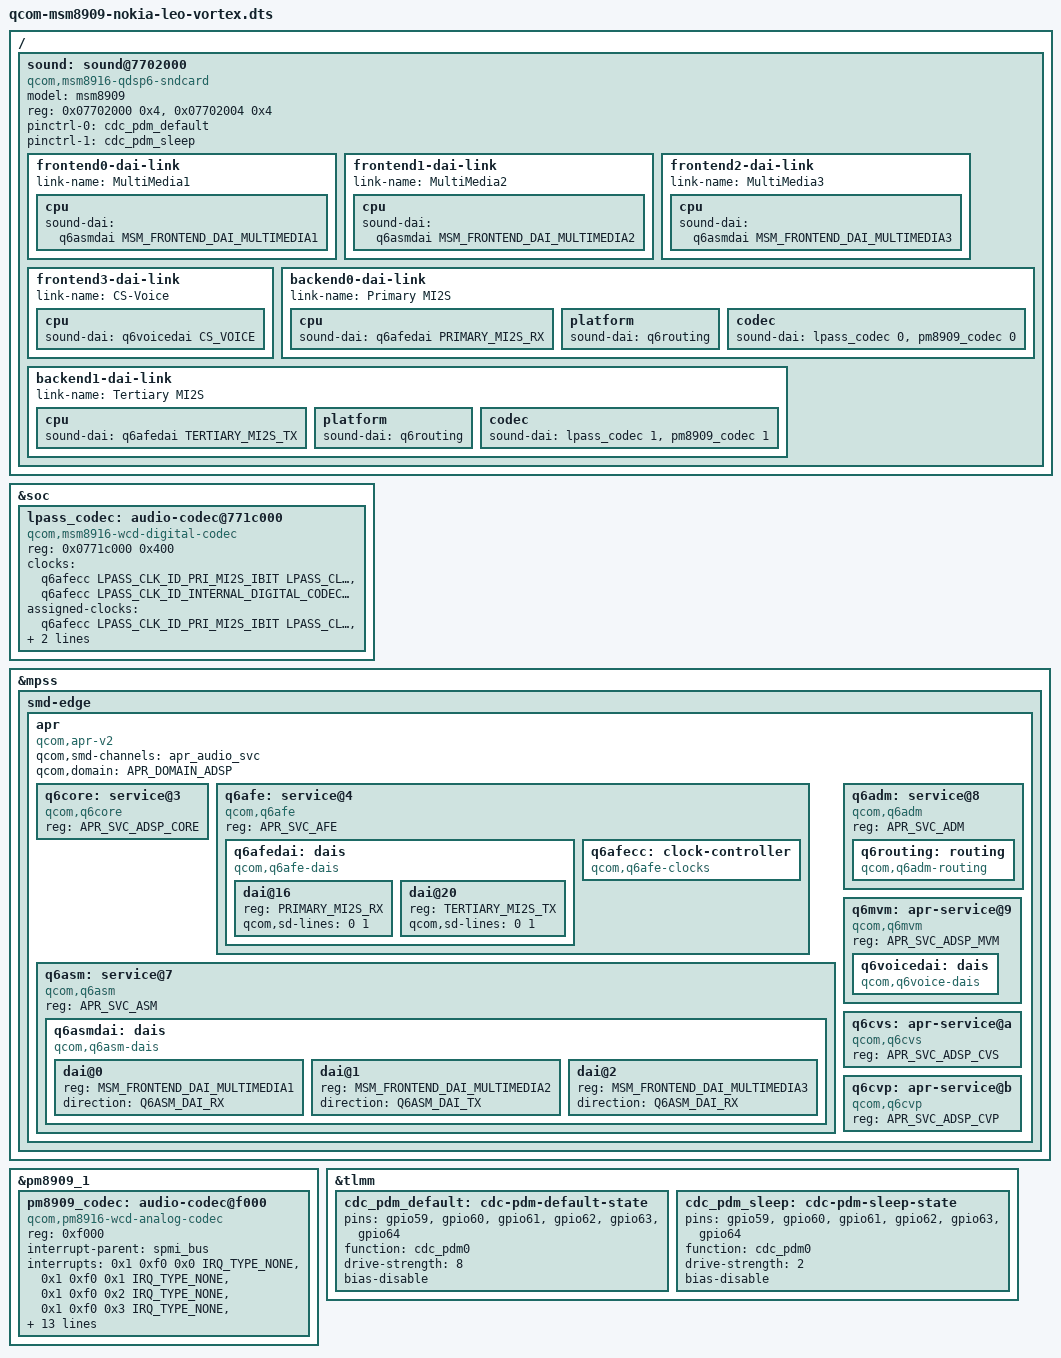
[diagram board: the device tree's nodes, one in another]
// SPDX-License-Identifier: GPL-2.0-only
/*
 * Nokia 6300 4G (nokia-leo) for Vortex: the postmarketOS / msm8916-mainline
 * device tree (tag v6.6-msm8916) plus audio, which that tree does not
 * describe for any MSM8909 device.
 *
 * Audio on MSM8909 goes through the QDSP6 services in the modem firmware,
 * like msm8916-modem-qdsp6.dtsi does for MSM8916 phones: the DSP owns the
 * audio interface (LPASS), the apps CPU drives the digital codec in the SoC
 * (0x771c000) and the analog codec in PM8909 (0xf000), linked by PDM.
 *
 * Differences from MSM8916, taken from Qualcomm's msm-3.18 MSM8909 sources:
 *  - GCC has no ULTAUDIO/CODEC_DIGCODEC clocks; the digital codec core
 *    clock is set through the DSP (AFE_PARAM_ID_CLOCK_SET with
 *    INTERNAL_DIGITAL_CODEC_CORE, as msm8952.c does by default), at the
 *    9.6 MHz of qcom,msm-mclk-freq.
 *  - The primary MI2S bit clock must be set the same way (CLOCK_SET,
 *    PRI_MI2S_IBIT, 1.536 MHz: msm8952.c mi2s_rx_clk).  The msm8916-qdsp6
 *    sound card sends the older LPAIF_CLK_CONFIG, which this firmware
 *    accepts but ignores: the stream then runs without the DSP taking any
 *    data.  The digital codec's "ahbix-clk" (the AHB interface clock, which
 *    the DSP handles on MSM8909) carries it instead, so it is on whenever
 *    the codec is.
 *  - PDM lines: gpio59-64, function cdc_pdm0 (msm8909-pinctrl.dtsi).
 *  - Codec supplies: L5 (1.8 V) for I/O and RX/TX, L13 (3.075 V) for the
 *    mic bias (msm-pm8909.dtsi).
 */

#include "qcom-msm8909-nokia-leo.dts"
#include <dt-bindings/soc/qcom,apr.h>
#include <dt-bindings/sound/qcom,q6afe.h>
#include <dt-bindings/sound/qcom,q6asm.h>
#include <dt-bindings/sound/qcom,q6voice.h>

/ {
	sound: sound@7702000 {
		compatible = "qcom,msm8916-qdsp6-sndcard";
		model = "msm8909";
		/* LPASS CSR I/O mux registers, the same on MSM8909 (msm8909-mtp.dtsi:
		 * csr_gp_io_mux_mic_ctl, csr_gp_io_mux_spkr_ctl); the driver
		 * refuses to probe without them */
		reg = <0x07702000 0x4>, <0x07702004 0x4>;
		reg-names = "mic-iomux", "spkr-iomux";

		pinctrl-0 = <&cdc_pdm_default>;
		pinctrl-1 = <&cdc_pdm_sleep>;
		pinctrl-names = "default", "sleep";

		frontend0-dai-link {
			link-name = "MultiMedia1";

			cpu {
				sound-dai = <&q6asmdai MSM_FRONTEND_DAI_MULTIMEDIA1>;
			};
		};

		frontend1-dai-link {
			link-name = "MultiMedia2";

			cpu {
				sound-dai = <&q6asmdai MSM_FRONTEND_DAI_MULTIMEDIA2>;
			};
		};

		frontend2-dai-link {
			link-name = "MultiMedia3";

			cpu {
				sound-dai = <&q6asmdai MSM_FRONTEND_DAI_MULTIMEDIA3>;
			};
		};

		frontend3-dai-link {
			link-name = "CS-Voice";

			cpu {
				sound-dai = <&q6voicedai CS_VOICE>;
			};
		};

		backend0-dai-link {
			link-name = "Primary MI2S";

			cpu {
				sound-dai = <&q6afedai PRIMARY_MI2S_RX>;
			};
			platform {
				sound-dai = <&q6routing>;
			};
			codec {
				sound-dai = <&lpass_codec 0>, <&pm8909_codec 0>;
			};
		};

		backend1-dai-link {
			link-name = "Tertiary MI2S";

			cpu {
				sound-dai = <&q6afedai TERTIARY_MI2S_TX>;
			};
			platform {
				sound-dai = <&q6routing>;
			};
			codec {
				sound-dai = <&lpass_codec 1>, <&pm8909_codec 1>;
			};
		};
	};
};

&soc {
	lpass_codec: audio-codec@771c000 {
		compatible = "qcom,msm8916-wcd-digital-codec";
		reg = <0x0771c000 0x400>;
		clocks = <&q6afecc LPASS_CLK_ID_PRI_MI2S_IBIT
				   LPASS_CLK_ATTRIBUTE_COUPLE_NO>,
			 <&q6afecc LPASS_CLK_ID_INTERNAL_DIGITAL_CODEC_CORE
				   LPASS_CLK_ATTRIBUTE_COUPLE_NO>;
		clock-names = "ahbix-clk", "mclk";
		/* DSP clocks only take their rate when they are switched on */
		assigned-clocks = <&q6afecc LPASS_CLK_ID_PRI_MI2S_IBIT
					    LPASS_CLK_ATTRIBUTE_COUPLE_NO>,
				  <&q6afecc LPASS_CLK_ID_INTERNAL_DIGITAL_CODEC_CORE
					    LPASS_CLK_ATTRIBUTE_COUPLE_NO>;
		assigned-clock-rates = <1536000>, <9600000>;
		#sound-dai-cells = <1>;
	};
};

&mpss {
	smd-edge {
		apr {
			compatible = "qcom,apr-v2";
			qcom,smd-channels = "apr_audio_svc";
			qcom,domain = <APR_DOMAIN_ADSP>;
			#address-cells = <1>;
			#size-cells = <0>;

			q6core: service@3 {
				compatible = "qcom,q6core";
				reg = <APR_SVC_ADSP_CORE>;
			};

			q6afe: service@4 {
				compatible = "qcom,q6afe";
				reg = <APR_SVC_AFE>;

				q6afedai: dais {
					compatible = "qcom,q6afe-dais";
					#address-cells = <1>;
					#size-cells = <0>;
					#sound-dai-cells = <1>;

					dai@16 {
						reg = <PRIMARY_MI2S_RX>;
						qcom,sd-lines = <0 1>;
					};

					dai@20 {
						reg = <TERTIARY_MI2S_TX>;
						qcom,sd-lines = <0 1>;
					};
				};

				q6afecc: clock-controller {
					compatible = "qcom,q6afe-clocks";
					#clock-cells = <2>;
				};
			};

			q6asm: service@7 {
				compatible = "qcom,q6asm";
				reg = <APR_SVC_ASM>;

				q6asmdai: dais {
					compatible = "qcom,q6asm-dais";
					#address-cells = <1>;
					#size-cells = <0>;
					#sound-dai-cells = <1>;

					dai@0 {
						reg = <MSM_FRONTEND_DAI_MULTIMEDIA1>;
						direction = <Q6ASM_DAI_RX>;
					};

					dai@1 {
						reg = <MSM_FRONTEND_DAI_MULTIMEDIA2>;
						direction = <Q6ASM_DAI_TX>;
					};

					dai@2 {
						reg = <MSM_FRONTEND_DAI_MULTIMEDIA3>;
						direction = <Q6ASM_DAI_RX>;
					};
				};
			};

			q6adm: service@8 {
				compatible = "qcom,q6adm";
				reg = <APR_SVC_ADM>;

				q6routing: routing {
					compatible = "qcom,q6adm-routing";
					#sound-dai-cells = <0>;
				};
			};

			q6mvm: apr-service@9 {
				compatible = "qcom,q6mvm";
				reg = <APR_SVC_ADSP_MVM>;

				q6voicedai: dais {
					compatible = "qcom,q6voice-dais";
					#sound-dai-cells = <0>;
				};
			};

			q6cvs: apr-service@a {
				compatible = "qcom,q6cvs";
				reg = <APR_SVC_ADSP_CVS>;
			};

			q6cvp: apr-service@b {
				compatible = "qcom,q6cvp";
				reg = <APR_SVC_ADSP_CVP>;
			};
		};
	};
};

&pm8909_1 {
	pm8909_codec: audio-codec@f000 {
		compatible = "qcom,pm8916-wcd-analog-codec";
		reg = <0xf000>;
		reg-names = "pmic-codec-core";
		interrupt-parent = <&spmi_bus>;
		interrupts = <0x1 0xf0 0x0 IRQ_TYPE_NONE>,
			     <0x1 0xf0 0x1 IRQ_TYPE_NONE>,
			     <0x1 0xf0 0x2 IRQ_TYPE_NONE>,
			     <0x1 0xf0 0x3 IRQ_TYPE_NONE>,
			     <0x1 0xf0 0x4 IRQ_TYPE_NONE>,
			     <0x1 0xf0 0x5 IRQ_TYPE_NONE>,
			     <0x1 0xf0 0x6 IRQ_TYPE_NONE>,
			     <0x1 0xf0 0x7 IRQ_TYPE_NONE>,
			     <0x1 0xf1 0x0 IRQ_TYPE_NONE>,
			     <0x1 0xf1 0x1 IRQ_TYPE_NONE>,
			     <0x1 0xf1 0x2 IRQ_TYPE_NONE>,
			     <0x1 0xf1 0x3 IRQ_TYPE_NONE>,
			     <0x1 0xf1 0x4 IRQ_TYPE_NONE>,
			     <0x1 0xf1 0x5 IRQ_TYPE_NONE>;
		interrupt-names = "cdc_spk_cnp_int",
				  "cdc_spk_clip_int",
				  "cdc_spk_ocp_int",
				  "mbhc_ins_rem_det1",
				  "mbhc_but_rel_det",
				  "mbhc_but_press_det",
				  "mbhc_ins_rem_det",
				  "mbhc_switch_int",
				  "cdc_ear_ocp_int",
				  "cdc_hphr_ocp_int",
				  "cdc_hphl_ocp_det",
				  "cdc_ear_cnp_int",
				  "cdc_hphr_cnp_int",
				  "cdc_hphl_cnp_int";
		vdd-cdc-io-supply = <&pm8909_l5>;
		vdd-cdc-tx-rx-cx-supply = <&pm8909_l5>;
		vdd-micbias-supply = <&pm8909_l13>;
		#sound-dai-cells = <1>;
	};
};

&tlmm {
	cdc_pdm_default: cdc-pdm-default-state {
		pins = "gpio59", "gpio60", "gpio61", "gpio62", "gpio63", "gpio64";
		function = "cdc_pdm0";
		drive-strength = <8>;
		bias-disable;
	};

	cdc_pdm_sleep: cdc-pdm-sleep-state {
		pins = "gpio59", "gpio60", "gpio61", "gpio62", "gpio63", "gpio64";
		function = "cdc_pdm0";
		drive-strength = <2>;
		bias-disable;
	};
};
